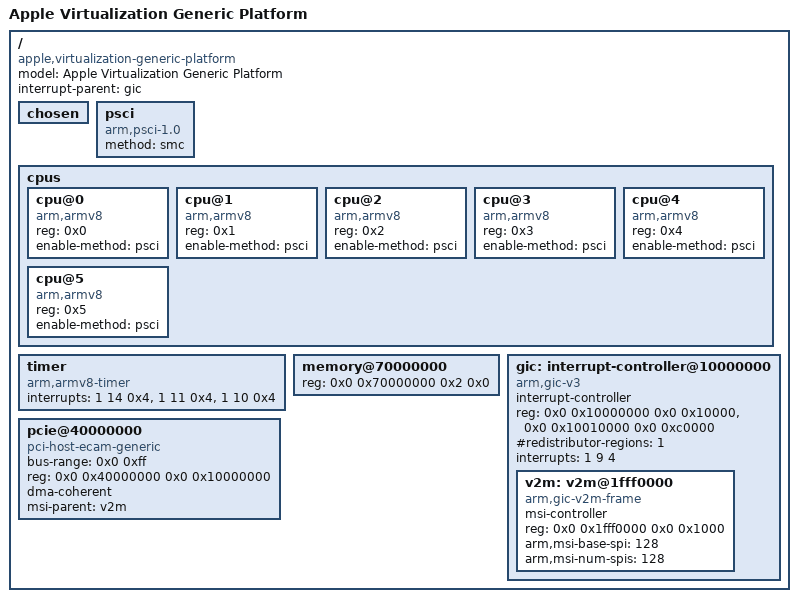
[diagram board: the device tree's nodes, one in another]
/dts-v1/;

/*
 * Apple Virtualization.framework generic platform, for Xen.
 *
 * Generated by plans/asahi/vz/gen-vz-dtb.py from this machine's ACPI
 * tables.  Do not hand-edit: re-generate after changing the VM's CPU
 * count, memory size or device set.
 */

/ {
	compatible = "apple,virtualization-generic-platform";
	model = "Apple Virtualization Generic Platform";
	#address-cells = <2>;
	#size-cells = <2>;
	interrupt-parent = <&gic>;

	chosen { };

	/*
	 * PSCI is how Xen starts the secondary CPUs.  The conduit is SMC even
	 * though there is no EL3: the outer hypervisor traps SMC from the
	 * whole nested guest, virtual EL2 included, and emulates it.
	 */
	psci {
		compatible = "arm,psci-1.0", "arm,psci-0.2";
		method = "smc";
	};

	cpus {
		#address-cells = <1>;
		#size-cells = <0>;

		cpu@0 {
			device_type = "cpu";
			compatible = "arm,armv8";
			reg = <0x0>;
			enable-method = "psci";
		};

		cpu@1 {
			device_type = "cpu";
			compatible = "arm,armv8";
			reg = <0x1>;
			enable-method = "psci";
		};

		cpu@2 {
			device_type = "cpu";
			compatible = "arm,armv8";
			reg = <0x2>;
			enable-method = "psci";
		};

		cpu@3 {
			device_type = "cpu";
			compatible = "arm,armv8";
			reg = <0x3>;
			enable-method = "psci";
		};

		cpu@4 {
			device_type = "cpu";
			compatible = "arm,armv8";
			reg = <0x4>;
			enable-method = "psci";
		};

		cpu@5 {
			device_type = "cpu";
			compatible = "arm,armv8";
			reg = <0x5>;
			enable-method = "psci";
		};

	};

	/*
	 * Xen runs on the non-secure EL2 physical timer, "hyp-phys".
	 */
	timer {
		compatible = "arm,armv8-timer";
		interrupt-names = "phys", "virt", "hyp-phys";
		interrupts = <1 14 0x4>,
		              <1 11 0x4>,
		              <1 10 0x4>;
	};

	memory@70000000 {
		device_type = "memory";
		reg = <0x0 0x70000000 0x2 0x0>;
	};

	gic: interrupt-controller@10000000 {
		compatible = "arm,gic-v3";
		#interrupt-cells = <3>;
		#address-cells = <2>;
		#size-cells = <2>;
		ranges;
		interrupt-controller;
		reg = <0x0 0x10000000 0x0 0x10000>,	/* GICD */
		      <0x0 0x10010000 0x0 0xc0000>;	/* GICR */
		#redistributor-regions = <1>;
		interrupts = <1 9 4>;

		/*
		 * The only MSI controller here.  It matters more than it looks:
		 * the PCI _PRT routes INTA for every slot while every device
		 * reports INTB, so MSIs are the only interrupts that work.
		 */
		v2m: v2m@1fff0000 {
			compatible = "arm,gic-v2m-frame";
			msi-controller;
			reg = <0x0 0x1fff0000 0x0 0x1000>;
			arm,msi-base-spi = <128>;
			arm,msi-num-spis = <128>;
		};
	};

	pcie@40000000 {
		compatible = "pci-host-ecam-generic";
		device_type = "pci";
		#address-cells = <3>;
		#size-cells = <2>;
		bus-range = <0x0 0xff>;
		reg = <0x0 0x40000000 0x0 0x10000000>;
		dma-coherent;
		msi-parent = <&v2m>;
		/*
		 * No interrupt-map and no #interrupt-cells: the firmware's _PRT
		 * describes INTA for each slot, but every device's Interrupt Pin
		 * register says INTB, so there is no legacy routing that would
		 * ever fire and nothing to describe.  Both Xen and Linux treat an
		 * absent interrupt-map as "no legacy interrupts" and go straight
		 * to MSI, which is the only thing that works here anyway.
		 */
		ranges = <0x02000000 0x0 0x50000000  0x0 0x50000000  0x0 0x1ffe0000>,
		          <0x03000000 0x2 0x80000000  0x2 0x80000000  0x4 0x0>;
	};
};
